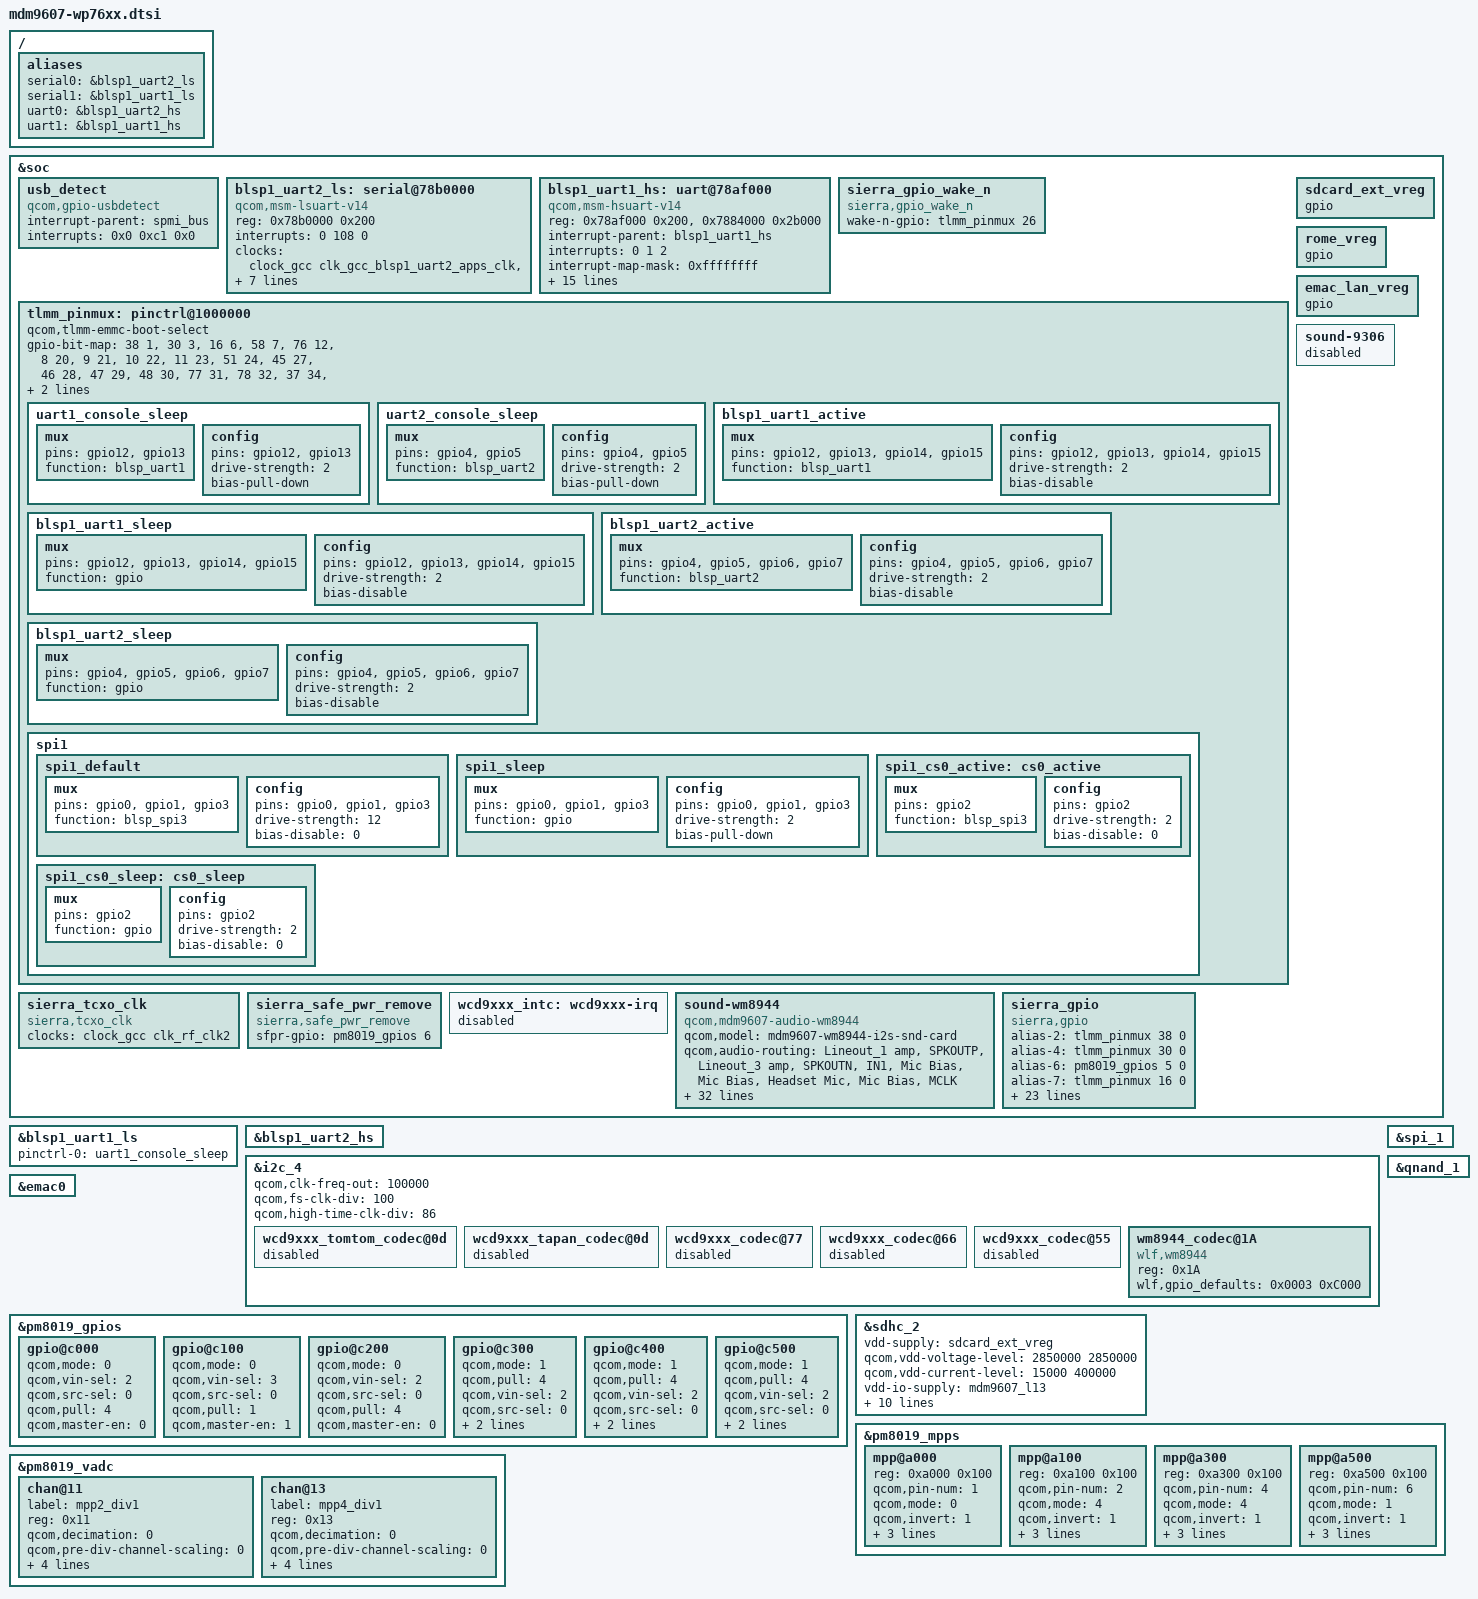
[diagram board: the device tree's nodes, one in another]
/*
 * Copyright (c) 2015-2016, The Linux Foundation. All rights reserved.
 *
 * This program is free software; you can redistribute it and/or modify
 * it under the terms of the GNU General Public License version 2 and
 * only version 2 as published by the Free Software Foundation.
 *
 * This program is distributed in the hope that it will be useful,
 * but WITHOUT ANY WARRANTY; without even the implied warranty of
 * MERCHANTABILITY or FITNESS FOR A PARTICULAR PURPOSE.  See the
 * GNU General Public License for more details.
 */
/*Inherit the shared DTS and overlay the difference */
#include "mdm9607-swi.dtsi"
#include "mdm9607-pinctrl.dtsi"
#include "mdm9607-swimcu.dtsi"
#include "mdm9607-sierra-monitor.dtsi"

/ {
	aliases {
		serial0 = &blsp1_uart2_ls; /* SWI:UART1 low speed */
		serial1 = &blsp1_uart1_ls; /* SWI:UART2 low speed */
		uart0 = &blsp1_uart2_hs;   /* SWI:UART1 high speed */
		uart1 = &blsp1_uart1_hs;   /* SWI:UART2 high speed */
	};
};

&soc {
	usb_detect {
		compatible = "qcom,gpio-usbdetect";
		interrupt-parent = <&spmi_bus>;
		/* PMIC GPIO 2 */
		interrupts = <0x0 0xc1 0x0>;
		interrupt-names = "vbus_det_irq";
	};

	blsp1_uart2_ls: serial@78b0000 { /* BLSP1 UART2, SWI:UART1, low speed */
		compatible = "qcom,msm-lsuart-v14";
		reg = <0x78b0000 0x200>;
		interrupts = <0 108 0>;

		clocks = <&clock_gcc clk_gcc_blsp1_uart2_apps_clk>,
			 <&clock_gcc clk_gcc_blsp1_ahb_clk>;
		clock-names = "core_clk", "iface_clk";
		qcom,msm-bus,name = "blsp1_uart2_ls";
		qcom,msm-bus,num-cases = <2>;
		qcom,msm-bus,num-paths = <1>;
		qcom,msm-bus,vectors-KBps =
					<86 512 0 0>,
					<86 512 500 800>;
		status = "disabled";
	};

	blsp1_uart1_hs: uart@78af000 { /* BLSP1 UART1, SWI:UART2, high speed */
		compatible = "qcom,msm-hsuart-v14";
		reg = <0x78af000 0x200>,
			<0x7884000 0x2b000>;
		reg-names = "core_mem", "bam_mem";
		interrupt-names = "core_irq", "bam_irq", "wakeup_irq";
		#address-cells = <0>;
		interrupt-parent = <&blsp1_uart1_hs>;
		interrupts = <0 1 2>;
		#interrupt-cells = <1>;
		interrupt-map-mask = <0xffffffff>;
		interrupt-map = <0 &intc 0 107 0
				1 &intc 0 238 0
				2 &tlmm_pinmux 13 0>;

		qcom,bam-tx-ep-pipe-index = <0>;
		qcom,bam-rx-ep-pipe-index = <1>;
		qcom,master-id = <86>;
		clock-names = "core_clk", "iface_clk";
		clocks = <&clock_gcc clk_gcc_blsp1_uart1_apps_clk>,
			<&clock_gcc clk_gcc_blsp1_ahb_clk>;
		pinctrl-names = "sleep", "default";
		pinctrl-0 = <&blsp1_uart1_sleep>;
		pinctrl-1 = <&blsp1_uart1_active>;
		qcom,msm-bus,name = "blsp1_uart1_hs";
		qcom,msm-bus,num-cases = <2>;
		qcom,msm-bus,num-paths = <1>;
		qcom,msm-bus,vectors-KBps =
					<86 512 0 0>,
					<86 512 500 800>;
		status = "disabled";
	};

	sierra_gpio_wake_n {
		compatible = "sierra,gpio_wake_n";
		wake-n-gpio = <&tlmm_pinmux 26 0>;
	};

	tlmm_pinmux: pinctrl@1000000 {
		/*undefine use of qcom,tlmm-emmc-boot-select*/
		qcom,tlmm-emmc-boot-select;

		gpio-bit-map =  <38 1>,
				<30 3>,
				<16 6>,
				<58 7>,
				<76 12>,
				<8 20>,
				<9 21>,
				<10 22>,
				<11 23>,
				<51 24>,
				<45 27>,
				<46 28>,
				<47 29>,
				<48 30>,
				<77 31>,
				<78 32>,
				<37 34>,
				<79 41>;
		gpio-RI = <25>;

        uart1_console_sleep: uart1_console_sleep {
			mux {
				pins = "gpio12", "gpio13";
				function = "blsp_uart1";
			};
			config {
				pins = "gpio12", "gpio13";
				drive-strength = <2>;
				bias-pull-down;
			};
		};

		uart2_console_sleep: uart2_console_sleep {
			mux {
				pins = "gpio4", "gpio5";
				function = "blsp_uart2";
			};
			config {
				pins = "gpio4", "gpio5";
				drive-strength = <2>;
				bias-pull-down;
			};
		};

		blsp1_uart1_active: blsp1_uart1_active {
			mux {
				pins = "gpio12", "gpio13", "gpio14", "gpio15";
				function = "blsp_uart1";
			};

			config {
				pins = "gpio12", "gpio13", "gpio14", "gpio15";
				drive-strength = <2>;
				bias-disable;
			};
		};

		blsp1_uart1_sleep: blsp1_uart1_sleep {
			mux {
				pins = "gpio12", "gpio13", "gpio14", "gpio15";
				function = "gpio";
			};

			config {
				pins = "gpio12", "gpio13", "gpio14", "gpio15";
				drive-strength = <2>;
				bias-disable;
			};
		};

		blsp1_uart2_active: blsp1_uart2_active {
			mux {
				pins = "gpio4", "gpio5", "gpio6", "gpio7";
				function = "blsp_uart2";
			};

			config {
				pins = "gpio4", "gpio5", "gpio6", "gpio7";
				drive-strength = <2>;
				bias-disable;
			};
		};

		blsp1_uart2_sleep: blsp1_uart2_sleep {
			mux {
				pins = "gpio4", "gpio5", "gpio6", "gpio7";
				function = "gpio";
			};


			config {
				pins = "gpio4", "gpio5", "gpio6", "gpio7";
				drive-strength = <2>;
				bias-disable;
			};
		};

		spi1 {

			spi1_default: spi1_default {
				/* active state */
				mux {
					/* MOSI, MISO, CLK */
					pins = "gpio0", "gpio1", "gpio3";
					function = "blsp_spi3";
				};

				config {
					pins = "gpio0", "gpio1", "gpio3";
					drive-strength = <12>; /* 12 MA */
					bias-disable = <0>; /* No PULL */
				};
			};

			spi1_sleep: spi1_sleep {
				/* suspended state */
				mux {
					/* MOSI, MISO, CLK */
					pins = "gpio0", "gpio1", "gpio3";
					function = "gpio";
				};

				config {
					pins = "gpio0", "gpio1", "gpio3";
					drive-strength = <2>; /* 2 MA */
					bias-pull-down; /* PULL Down */
				};
			};

			spi1_cs0_active: cs0_active {
				/* CS */
				mux {
					pins = "gpio2";
					function = "blsp_spi3";
				};

				config {
					pins = "gpio2";
					drive-strength = <2>;
					bias-disable = <0>;
				};
			};

			spi1_cs0_sleep: cs0_sleep {
				/* CS */
				mux {
					pins = "gpio2";
					function = "gpio";
				};

				config {
					pins = "gpio2";
					drive-strength = <2>;
					bias-disable = <0>;
				};
			};
		};
	};

	sdcard_ext_vreg: sdcard_ext_vreg {
	/*undefine use of pm-gpio4, we don't use pm-gpio4 for sdcard_ext_vreg*/
		gpio;
	};

	rome_vreg: rome_vreg {
	/*undefine use of pm-gpio3, we don't use pm-gpio3 for rome_vreg*/
		gpio;
	};

	emac_lan_vreg: emac_lan_vreg {
	/* undefine use of mpp4, as we don't use mpp4 for this function */
		gpio;
	};

	sierra_tcxo_clk {
		compatible = "sierra,tcxo_clk";
		clocks = <&clock_gcc clk_rf_clk2>;
		clock-names = "tcxo_clk";
	};

	sierra_safe_pwr_remove {
		compatible = "sierra,safe_pwr_remove";
		sfpr-gpio = <&pm8019_gpios 6 0>;
	};

	sound-9306 {
		status = "disabled";
	};

	wcd9xxx_intc: wcd9xxx-irq {
		status = "disabled";
	};

	sound-wm8944 {
		compatible = "qcom,mdm9607-audio-wm8944";
		qcom,model = "mdm9607-wm8944-i2s-snd-card";

		qcom,audio-routing =
			"Lineout_1 amp", "SPKOUTP",
			"Lineout_3 amp", "SPKOUTN",
			"IN1", "Mic Bias",
			"Mic Bias", "Headset Mic",
			"Mic Bias", "MCLK";

		qcom,codec-mclk-clk-freq = <19200000>;
		qcom,mi2s-interface-mode = "pri_mi2s_master", "sec_mi2s_master";
		qcom,auxpcm-interface-mode = "pri_pcm_master", "sec_pcm_master";
		asoc-platform = <&pcm0>, <&pcm1>, <&voip>, <&voice>,
				<&loopback>, <&hostless>, <&afe>, <&routing>,
				<&pcm_dtmf>, <&host_pcm>, <&compress>;
		asoc-platform-names = "msm-pcm-dsp.0", "msm-pcm-dsp.1",
				"msm-voip-dsp", "msm-pcm-voice",
				"msm-pcm-loopback", "msm-pcm-hostless",
				"msm-pcm-afe", "msm-pcm-routing",
				"msm-pcm-dtmf", "msm-voice-host-pcm",
				"msm-compress-dsp";
		asoc-cpu = <&dai_pri_auxpcm>, <&dai_sec_auxpcm>,
				<&mi2s_prim>, <&mi2s_sec>, <&dtmf_tx>,
				<&rx_capture_tx>, <&rx_playback_rx>,
				<&tx_capture_tx>, <&tx_playback_rx>,
				<&afe_pcm_rx>, <&afe_pcm_tx>, <&afe_proxy_rx>,
				<&afe_proxy_tx>, <&incall_record_rx>,
				<&incall_record_tx>, <&incall_music_rx>;
		asoc-cpu-names = "msm-dai-q6-auxpcm.1", "msm-dai-q6-auxpcm.2",
				"msm-dai-q6-mi2s.0", "msm-dai-q6-mi2s.1",
				"msm-dai-stub-dev.4", "msm-dai-stub-dev.5",
				"msm-dai-stub-dev.6", "msm-dai-stub-dev.7",
				"msm-dai-stub-dev.8", "msm-dai-q6-dev.224",
				"msm-dai-q6-dev.225", "msm-dai-q6-dev.241",
				"msm-dai-q6-dev.240", "msm-dai-q6-dev.32771",
				"msm-dai-q6-dev.32772", "msm-dai-q6-dev.32773";
		asoc-codec = <&stub_codec>;
		asoc-codec-names = "msm-stub-codec.1";
		clocks = <&clock_gcc clk_rf_clk2>;
		clock-names = "wm8944_sysclk";
	};

	sierra_gpio {
		compatible = "sierra,gpio";
		alias-2 = <&tlmm_pinmux 38 0>;
		alias-4 = <&tlmm_pinmux 30 0>;
		alias-6 = <&pm8019_gpios 5 0>;
		alias-7 = <&tlmm_pinmux 16 0>;
		alias-8 = <&tlmm_pinmux 58 0>;
		alias-13 = <&tlmm_pinmux 76 0>;
		alias-21 = <&tlmm_pinmux 8 0>;
		alias-22 = <&tlmm_pinmux 9 0>;
		alias-23 = <&tlmm_pinmux 10 0>;
		alias-24 = <&tlmm_pinmux 11 0>;
		alias-25 = <&tlmm_pinmux 51 0>;
		alias-28 = <&tlmm_pinmux 45 0>;
		alias-29 = <&tlmm_pinmux 46 0>;
		alias-30 = <&tlmm_pinmux 47 0>;
		alias-31 = <&tlmm_pinmux 48 0>;
		alias-32 = <&tlmm_pinmux 77 0>;
		alias-33 = <&tlmm_pinmux 78 0>;
		alias-35 = <&tlmm_pinmux 37 0>;
                /* Like SWIMCU pinctrl is not defined inside the device tree,
                 * it requires to know the SWIMCU gpio base address: 200
		 * see: SWIMCU_GPIO_BASE in arch/arm/mach-msm/include/mach/swimcu.h
		 */
		alias-36 = <200 0>;
		alias-37 = <201 0>;
		alias-38 = <202 0>;
		alias-40 = <203 0>;
		alias-41 = <204 0>;
		alias-42 = <&tlmm_pinmux 79 0>;
		alias-RI = <&tlmm_pinmux 25 0>;
		/* WIFI aliases */
		alias-WLAN_EN = <&tlmm_pinmux 58 0>;
		alias-WIFI_IRQ = <&tlmm_pinmux 79 0>;
	};
};

&blsp1_uart1_hs {
	status = "ok";
};

&blsp1_uart1_ls {
	status = "ok";
	pinctrl-names = "default";
	pinctrl-0 = <&uart1_console_sleep>;
};

&blsp1_uart2_hs {
	status = "ok";
};

&blsp1_uart2_ls {
	status = "ok";
	pinctrl-names = "default";
	pinctrl-0 = <&uart2_console_sleep>;
};


&i2c_4 {
	/* reduce bus frequency as a workaround for MCU ROM boot loader */
	qcom,clk-freq-out = <100000>;

	/* Increase clock high width from 3.4ns to 4.6ns to meet I2C spec */
	qcom,fs-clk-div = <100>;
	qcom,high-time-clk-div = <86>;
	status = "ok";
};

&spi_1 {
	status = "ok";
};

&qnand_1 {
	status = "ok";
};

&emac0 {
	status = "ok";
};

&pm8019_gpios {

	/* HW revision minor bit 1: read once in boot loader
	*  Override to prevent possible current leaks.
	*/
	gpio@c000 { /* GPIO 1 */
		qcom,mode = <0>;         /* Digital input */
		qcom,vin-sel = <2>;      /* 1.8V (L11) */
		qcom,src-sel = <0>;      /* GPIO */
		qcom,pull = <4>;         /* QPNP_PIN_PULL_DOWN */
		qcom,master-en = <0>;    /* Disable to prevent current leaks*/
		status = "ok";
	};

	/* VBUS detect */
	gpio@c100 { /* GPIO 2 */
		qcom,mode = <0>;        /* Digital input */
		qcom,vin-sel = <3>;     /* 1.8V (L11) */
		qcom,src-sel = <0>;     /* QPNP_PIN_SEL_FUNC_CONSTANT */
		qcom,pull = <1>;        /* NO PULL */
		qcom,master-en = <1>;
		status = "ok";
	};

	/* HW revision minor bit 0: read once in boot loader
	*  Override to prevent possible current leaks.
	*/
	gpio@c200 { /* GPIO 3 */
		qcom,mode = <0>;         /* Digital input */
		qcom,vin-sel = <2>;      /* 1.8V (L11) */
		qcom,src-sel = <0>;      /* GPIO */
		qcom,pull = <4>;         /* QPNP_PIN_PULL_DOWN */
		qcom,master-en = <0>;    /* Disable to prevent current leaks*/
		status = "ok";
	};

	gpio@c300 { /* GPIO 4 */
		qcom,mode = <1>;         /* Digital output*/
		qcom,pull = <4>;         /* Pulldown 10uA */
		qcom,vin-sel = <2>;      /* VIN2 */
		qcom,src-sel = <0>;      /* GPIO */
		qcom,invert = <0>;       /* Invert */
		qcom,master-en = <1>;    /* Enable GPIO */
		status = "ok";
	};

	gpio@c400 { /* GPIO 5 */
		qcom,mode = <1>;         /* Digital output*/
		qcom,pull = <4>;         /* Pulldown 10uA */
		qcom,vin-sel = <2>;      /* VIN2 */
		qcom,src-sel = <0>;      /* GPIO */
		qcom,invert = <1>;       /* Invert */
		qcom,master-en = <1>;    /* Enable GPIO */
		status = "ok";
	};

	gpio@c500 { /* GPIO 6 */
		qcom,mode = <1>;         /* Digital output*/
		qcom,pull = <4>;         /* Pulldown 10uA */
		qcom,vin-sel = <2>;      /* VIN2 */
		qcom,src-sel = <0>;      /* GPIO */
		qcom,invert = <0>;       /* Invert */
		qcom,master-en = <1>;    /* Enable GPIO */
		status = "ok";
	};
};

&sdhc_2 {
	vdd-supply = <&sdcard_ext_vreg>;
	qcom,vdd-voltage-level = <2850000 2850000>;
	qcom,vdd-current-level = <15000 400000>;

	vdd-io-supply = <&mdm9607_l13>;
	qcom,vdd-io-voltage-level = <1800000 2850000>;
	qcom,vdd-io-current-level = <200 50000>;

	#address-cells = <0>;
	interrupt-parent = <&sdhc_2>;
	interrupts = <0 1>;
	#interrupt-cells = <1>;
	interrupt-map-mask = <0xffffffff>;
	interrupt-map = <0 &intc 0 125 0
			1 &intc 0 221 0>;
	interrupt-names = "hc_irq", "pwr_irq";

	pinctrl-names = "active", "sleep";
	pinctrl-0 = <&sdc2_clk_on &sdc2_cmd_on &sdc2_data_on &sdc2_cd_on>;
	pinctrl-1 = <&sdc2_clk_off &sdc2_cmd_off &sdc2_data_off>;

	status = "ok";
};

&pm8019_mpps {
	/* MPP1 */
	mpp@a000 {
		reg = <0xa000 0x100>;
		qcom,pin-num = <1>;

		qcom,mode = <0>; /* DIG input */
		qcom,invert = <1>; /* Enable MPP */
		qcom,vin-sel = <3>;
		qcom,master-en = <1>;
		qcom,src-sel = <0>; /* Function constant */
		status = "ok";
	};

	/* MPP2 */
	mpp@a100 {
		reg = <0xa100 0x100>;
		qcom,pin-num = <2>;

		qcom,mode = <4>; /* AIN input */
		qcom,invert = <1>; /* Enable MPP */
		qcom,ain-route = <1>; /* AMUX 6 */
		qcom,master-en = <1>;
		qcom,src-sel = <0>; /* Function constant */
		status = "ok";
	};

	/* MPP4 */
	mpp@a300 {
		reg = <0xa300 0x100>;
		qcom,pin-num = <4>;

		qcom,mode = <4>; /* AIN input */
		qcom,invert = <1>; /* Enable MPP */
		qcom,ain-route = <3>; /* AMUX 8 */
		qcom,master-en = <1>;
		qcom,src-sel = <0>; /* Function constant */
		status = "ok";
	};

	/* MPP6 */
	mpp@a500 {
		reg = <0xa500 0x100>;
		qcom,pin-num = <6>;

		qcom,mode = <1>; /* DIG output */
		qcom,invert = <1>; /* Enable MPP */
		qcom,vin-sel = <2>;
		qcom,master-en = <1>;
		qcom,src-sel = <0>; /* Function constant */
		status = "ok";
	};
};

&pm8019_vadc {
	/* VADC Channel configuration MPP2 scaling 1/1*/
	chan@11 {
		label = "mpp2_div1";
		reg = <0x11>;
		qcom,decimation = <0>;
		qcom,pre-div-channel-scaling = <0>; //1:1 scaling
		qcom,calibration-type = "absolute"; //1.25v ref-vcc
		qcom,scale-function = <0>;
		qcom,hw-settle-time = <2>; //200us
		qcom,fast-avg-setup = <0>;
	};
	/* VADC Channel configuration MPP4 scaling 1/1*/
	chan@13 {
		label = "mpp4_div1";
		reg = <0x13>;
		qcom,decimation = <0>;
		qcom,pre-div-channel-scaling = <0>; //1:1 scaling
		qcom,calibration-type = "absolute"; //1.25v ref-vcc
		qcom,scale-function = <0>;
		qcom,hw-settle-time = <2>; //200us
		qcom,fast-avg-setup = <0>;
	};
};

/* Disable the the codec dts */
&i2c_4 {
	wcd9xxx_tomtom_codec@0d{
		status = "disabled";
	};

	wcd9xxx_tapan_codec@0d{
		status = "disabled";
	};

	wcd9xxx_codec@77{
		status = "disabled";
	};

	wcd9xxx_codec@66{
		status = "disabled";
	};

	wcd9xxx_codec@55{
		status = "disabled";
	};

	wm8944_codec@1A{
		compatible = "wlf,wm8944";
		reg = <0x1A>;
		wlf,gpio_defaults = <0x0003 0xC000>;
	};
};
